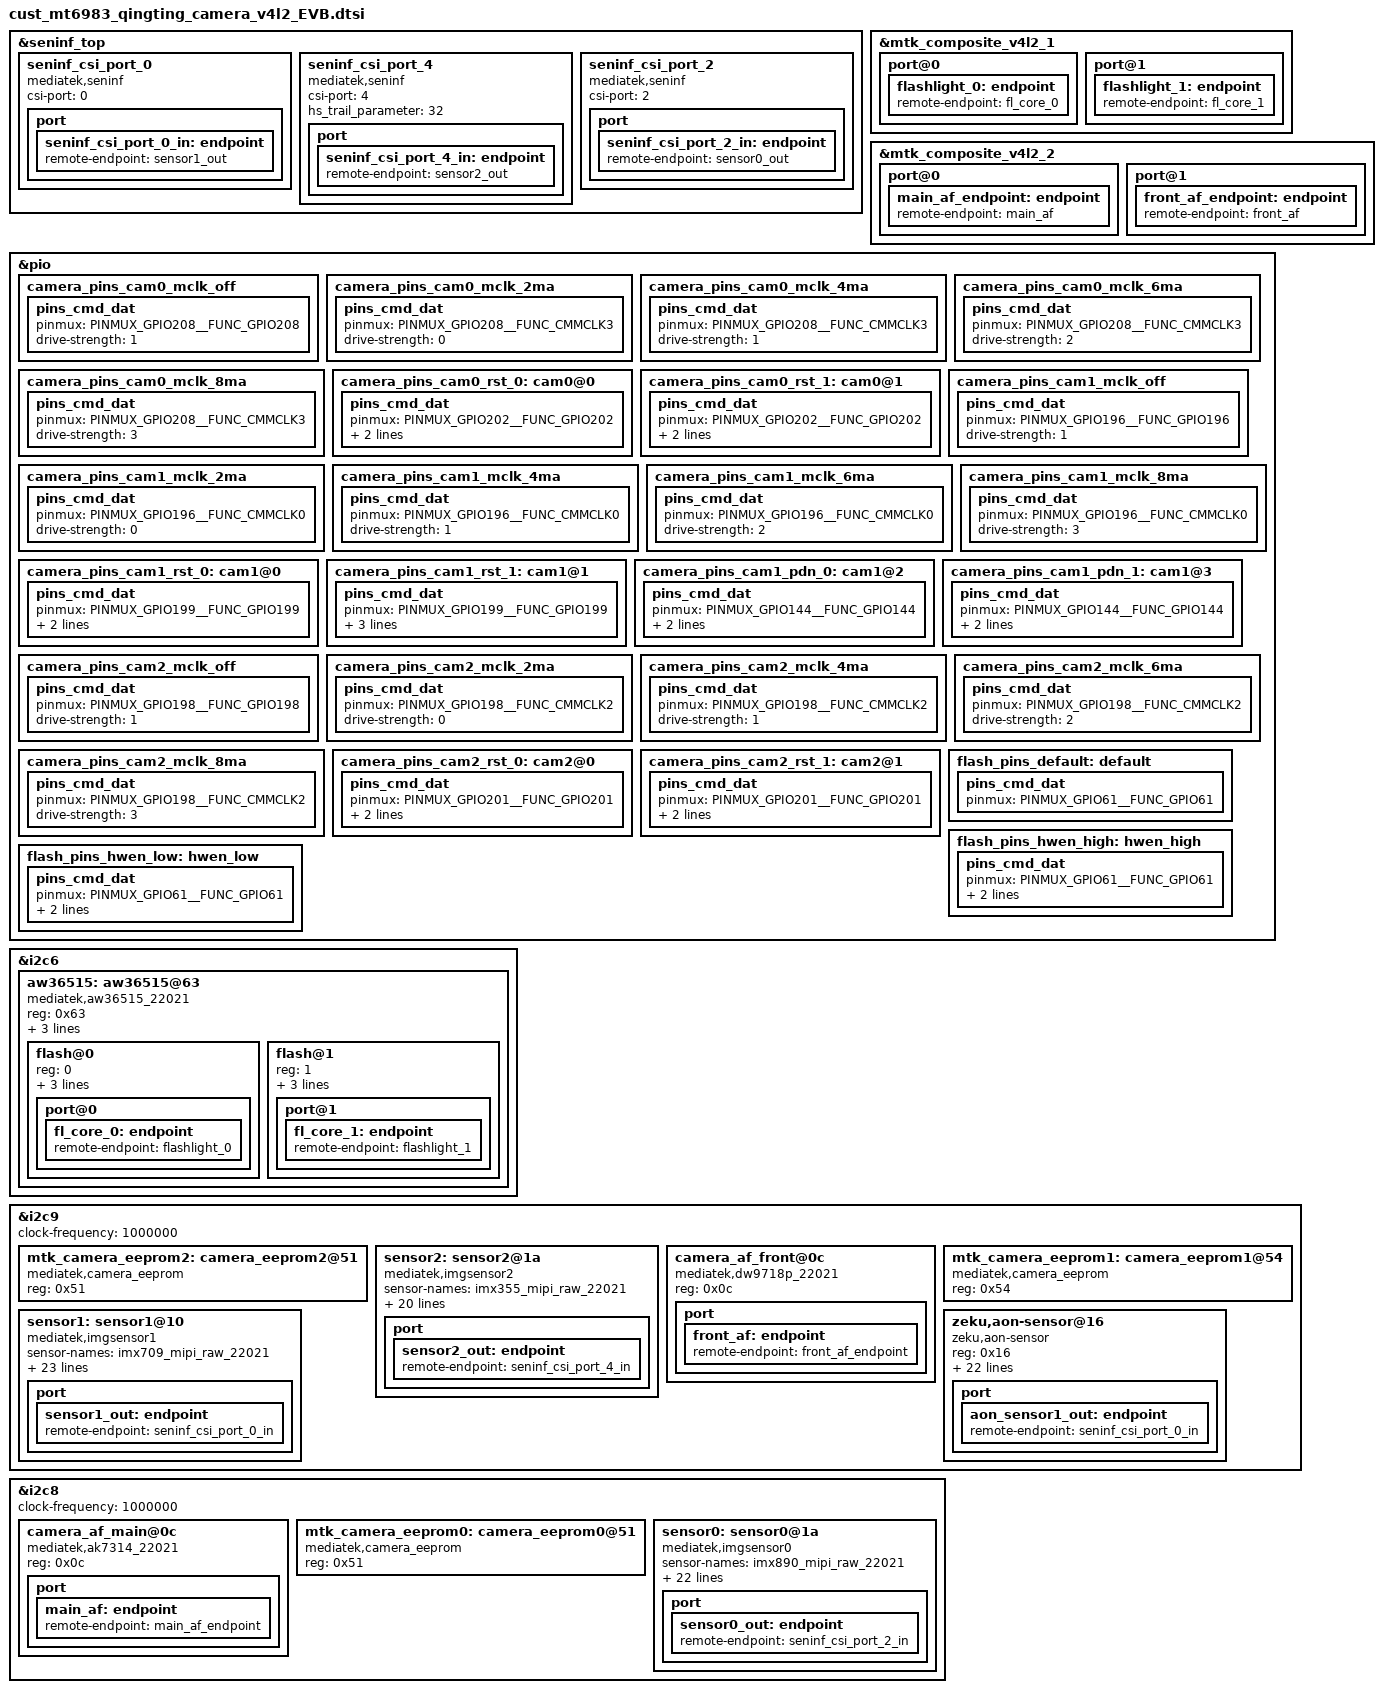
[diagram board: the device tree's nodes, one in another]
// SPDX-License-Identifier: GPL-2.0-only
/*
* Copyright (C) 2021 Oplus. All rights reserved.
*/

#include <dt-bindings/clock/mt6983-clk.h>

&seninf_top {
    seninf_csi_port_0: seninf_csi_port_0 {
        compatible = "mediatek,seninf";
        csi-port = "0";
        //seninf_dphy_settle_delay_dt = <14>;
#if 0
        nvmem-cells = <&csi_efuse0>;
        nvmem-cell-names = "rg_csi";
#endif
        port {
            seninf_csi_port_0_in: endpoint {
                remote-endpoint = <&sensor1_out>;
            };
        };
    };

    seninf_csi_port_4: seninf_csi_port_4 {
        compatible = "mediatek,seninf";
        csi-port = "4";
        hs_trail_parameter = <32>;
#if 0
        nvmem-cells = <&csi_efuse1>;
        nvmem-cell-names = "rg_csi";
#endif
        port {
            seninf_csi_port_4_in: endpoint {
                remote-endpoint = <&sensor2_out>;
            };
        };
    };

    seninf_csi_port_2: seninf_csi_port_2 {
        compatible = "mediatek,seninf";
        csi-port = "2";
#if 0
        nvmem-cells = <&csi_efuse2>;
        nvmem-cell-names = "rg_csi";
#endif
        port {
            seninf_csi_port_2_in: endpoint {
                remote-endpoint = <&sensor0_out>;
            };
        };
    };
};

&mtk_composite_v4l2_1 {
port@0 {
        flashlight_0: endpoint {
            remote-endpoint = <&fl_core_0>;
        };
    };
    port@1 {
        flashlight_1: endpoint {
            remote-endpoint = <&fl_core_1>;
        };
    };
};

&mtk_composite_v4l2_2 {
    port@0 {
        main_af_endpoint: endpoint {
            remote-endpoint = <&main_af>;
        };
    };
    port@1 {
        front_af_endpoint: endpoint {
            remote-endpoint = <&front_af>;
        };
    };
};

&pio {
    camera_pins_cam0_mclk_off: camera_pins_cam0_mclk_off {
        pins_cmd_dat {
            pinmux = <PINMUX_GPIO208__FUNC_GPIO208>;
            drive-strength = <1>;
        };
    };
    camera_pins_cam0_mclk_2ma: camera_pins_cam0_mclk_2ma {
        pins_cmd_dat {
            pinmux = <PINMUX_GPIO208__FUNC_CMMCLK3>;
            drive-strength = <0>;
        };
    };
    camera_pins_cam0_mclk_4ma: camera_pins_cam0_mclk_4ma {
        pins_cmd_dat {
            pinmux = <PINMUX_GPIO208__FUNC_CMMCLK3>;
            drive-strength = <1>;
        };
    };
    camera_pins_cam0_mclk_6ma: camera_pins_cam0_mclk_6ma {
        pins_cmd_dat {
            pinmux = <PINMUX_GPIO208__FUNC_CMMCLK3>;
            drive-strength = <2>;
        };
    };
    camera_pins_cam0_mclk_8ma: camera_pins_cam0_mclk_8ma {
        pins_cmd_dat {
            pinmux = <PINMUX_GPIO208__FUNC_CMMCLK3>;
            drive-strength = <3>;
        };
    };
    camera_pins_cam0_rst_0: cam0@0 {
        pins_cmd_dat {
            pinmux = <PINMUX_GPIO202__FUNC_GPIO202>;
            slew-rate = <1>;
            output-low;
        };
    };
    camera_pins_cam0_rst_1: cam0@1 {
        pins_cmd_dat {
            pinmux = <PINMUX_GPIO202__FUNC_GPIO202>;
            slew-rate = <1>;
            output-high;
        };
    };

    camera_pins_cam1_mclk_off: camera_pins_cam1_mclk_off {
        pins_cmd_dat {
            pinmux = <PINMUX_GPIO196__FUNC_GPIO196>;
            drive-strength = <1>;
        };
    };
    camera_pins_cam1_mclk_2ma: camera_pins_cam1_mclk_2ma {
        pins_cmd_dat {
            pinmux = <PINMUX_GPIO196__FUNC_CMMCLK0>;
            drive-strength = <0>;
        };
    };
    camera_pins_cam1_mclk_4ma: camera_pins_cam1_mclk_4ma {
        pins_cmd_dat {
            pinmux = <PINMUX_GPIO196__FUNC_CMMCLK0>;
            drive-strength = <1>;
        };
    };
    camera_pins_cam1_mclk_6ma: camera_pins_cam1_mclk_6ma {
        pins_cmd_dat {
            pinmux = <PINMUX_GPIO196__FUNC_CMMCLK0>;
            drive-strength = <2>;
        };
    };
    camera_pins_cam1_mclk_8ma: camera_pins_cam1_mclk_8ma {
        pins_cmd_dat {
            pinmux = <PINMUX_GPIO196__FUNC_CMMCLK0>;
            drive-strength = <3>;
        };
    };
    camera_pins_cam1_rst_0: cam1@0 {
        pins_cmd_dat {
            pinmux = <PINMUX_GPIO199__FUNC_GPIO199>;
            slew-rate = <1>;
            output-low;
        };
    };
    camera_pins_cam1_rst_1: cam1@1 {
        pins_cmd_dat {
            pinmux = <PINMUX_GPIO199__FUNC_GPIO199>;
            drive-strength = <3>;
            slew-rate = <1>;
            output-high;
        };
    };
    camera_pins_cam1_pdn_0: cam1@2 {
        pins_cmd_dat {
            pinmux = <PINMUX_GPIO144__FUNC_GPIO144>;
            slew-rate = <1>;
            output-low;
        };
    };
    camera_pins_cam1_pdn_1: cam1@3 {
        pins_cmd_dat {
            pinmux = <PINMUX_GPIO144__FUNC_GPIO144>;
            slew-rate = <1>;
            output-high;
        };
    };

    camera_pins_cam2_mclk_off: camera_pins_cam2_mclk_off {
        pins_cmd_dat {
            pinmux = <PINMUX_GPIO198__FUNC_GPIO198>;
            drive-strength = <1>;
        };
    };
    camera_pins_cam2_mclk_2ma: camera_pins_cam2_mclk_2ma {
        pins_cmd_dat {
            pinmux = <PINMUX_GPIO198__FUNC_CMMCLK2>;
            drive-strength = <0>;
        };
    };
    camera_pins_cam2_mclk_4ma: camera_pins_cam2_mclk_4ma {
        pins_cmd_dat {
            pinmux = <PINMUX_GPIO198__FUNC_CMMCLK2>;
            drive-strength = <1>;
        };
    };
    camera_pins_cam2_mclk_6ma: camera_pins_cam2_mclk_6ma {
        pins_cmd_dat {
            pinmux = <PINMUX_GPIO198__FUNC_CMMCLK2>;
            drive-strength = <2>;
        };
    };
    camera_pins_cam2_mclk_8ma: camera_pins_cam2_mclk_8ma {
        pins_cmd_dat {
            pinmux = <PINMUX_GPIO198__FUNC_CMMCLK2>;
            drive-strength = <3>;
        };
    };
    camera_pins_cam2_rst_0: cam2@0 {
        pins_cmd_dat {
            pinmux = <PINMUX_GPIO201__FUNC_GPIO201>;
            slew-rate = <1>;
            output-low;
        };
    };
    camera_pins_cam2_rst_1: cam2@1 {
        pins_cmd_dat {
            pinmux = <PINMUX_GPIO201__FUNC_GPIO201>;
            slew-rate = <1>;
            output-high;
        };
    };

    flash_pins_default: default {
            pins_cmd_dat {
                    pinmux = <PINMUX_GPIO61__FUNC_GPIO61>;
            };
    };

    flash_pins_hwen_high: hwen_high {
            pins_cmd_dat {
                    pinmux = <PINMUX_GPIO61__FUNC_GPIO61>;
                    slew-rate = <1>;
                    output-high;
            };
    };

    flash_pins_hwen_low: hwen_low {
            pins_cmd_dat {
                    pinmux = <PINMUX_GPIO61__FUNC_GPIO61>;
                    slew-rate = <1>;
                    output-low;
            };
    };
};

/*Flash light*/
&i2c6 {
    aw36515:aw36515@63 {
        compatible = "mediatek,aw36515_22021";
        reg = <0x63>;
        #cooling-cells = <2>;
        pinctrl-names = "default", "hwen_high", "hwen_low";
        pinctrl-0 = <&flash_pins_default>;
        pinctrl-1 = <&flash_pins_hwen_high>;
        pinctrl-2 = <&flash_pins_hwen_low>;
        status = "okay";
        flash@0{
            reg = <0>;
            type = <0>;
            ct = <0>;
            part = <0>;
            port@0 {
                fl_core_0: endpoint {
                    remote-endpoint = <&flashlight_0>;
                };
            };
        };
        flash@1{
            reg = <1>;
            type = <0>;
            ct = <1>;
            part = <0>;
            port@1 {
                fl_core_1: endpoint {
                    remote-endpoint = <&flashlight_1>;
                };
            };
        };
    };
};

&i2c9 {
    clock-frequency = <1000000>;
    mtk_camera_eeprom2:camera_eeprom2@51 {
        compatible = "mediatek,camera_eeprom";
        reg = <0x51>;
        status = "okay";
    };

    sensor2: sensor2@1a {
        compatible = "mediatek,imgsensor2";
        sensor-names = "imx355_mipi_raw_22021";
        reg = <0x1a>;
        pinctrl-names = "mclk_off",
                "mclk_2mA",
                "mclk_4mA",
                "mclk_6mA",
                "mclk_8mA",
                "rst_low",
                "rst_high";
        //GPIO198
        pinctrl-0 = <&camera_pins_cam2_mclk_off>;
        pinctrl-1 = <&camera_pins_cam2_mclk_2ma>;
        pinctrl-2 = <&camera_pins_cam2_mclk_4ma>;
        pinctrl-3 = <&camera_pins_cam2_mclk_6ma>;
        pinctrl-4 = <&camera_pins_cam2_mclk_8ma>;
        //GPIO201
        pinctrl-5 = <&camera_pins_cam2_rst_0>;
        pinctrl-6 = <&camera_pins_cam2_rst_1>;

        dvdd-supply = <&wl2868c_ldo1a>;
        avdd-supply = <&wl2868c_ldo5a>;
        dovdd-supply = <&fan53870_ldo6b>;

        clocks = <&topckgen_clk CLK_TOPCKGEN_UNIVPLL_192M_D32>,
            <&topckgen_clk CLK_TOPCKGEN_UNIVPLL_192M_D16>,
            <&topckgen_clk CLK_TOPCKGEN_F_F26M_CK_D2>,
            <&topckgen_clk CLK_TOPCKGEN_UNIVPLL_192M_D10>,
            <&topckgen_clk CLK_TOPCKGEN_UNIVPLL_192M_D8>,
            <&clk26m>,
            <&topckgen_clk CLK_TOPCKGEN_UNIVPLL_D6_D8>,
            <&topckgen_clk CLK_TOPCKGEN_CAMTG3_SEL>;
        clock-names = "6", "12", "13", "19.2", "24", "26", "52", "mclk";

        status = "okay";

        port {
            sensor2_out: endpoint {
                remote-endpoint = <&seninf_csi_port_4_in>;
            };
        };
    };
};

&i2c8 {
    clock-frequency = <1000000>;
    /* MAIN */
    camera_af_main@0c {
        compatible = "mediatek,ak7314_22021";
        reg = <0x0c>;
        port {
            main_af: endpoint {
                remote-endpoint = <&main_af_endpoint>;
            };
        };
    };
    mtk_camera_eeprom0:camera_eeprom0@51 {
        compatible = "mediatek,camera_eeprom";
        reg = <0x51>;
        status = "okay";
    };

    sensor0: sensor0@1a {
        compatible = "mediatek,imgsensor0";
        sensor-names = "imx890_mipi_raw_22021";
        reg = <0x1a>;
        pinctrl-names = "mclk_off",
                "mclk_2mA",
                "mclk_4mA",
                "mclk_6mA",
                "mclk_8mA",
                "rst_low",
                "rst_high";
        //GPIO208
        pinctrl-0 = <&camera_pins_cam0_mclk_off>;
        pinctrl-1 = <&camera_pins_cam0_mclk_2ma>;
        pinctrl-2 = <&camera_pins_cam0_mclk_4ma>;
        pinctrl-3 = <&camera_pins_cam0_mclk_6ma>;
        pinctrl-4 = <&camera_pins_cam0_mclk_8ma>;
        //GPIO202
        pinctrl-5 = <&camera_pins_cam0_rst_0>;
        pinctrl-6 = <&camera_pins_cam0_rst_1>;

        avdd-supply = <&wl2868c_ldo3a>;
        avdd1-supply = <&fan53870_ldo5b>;
        afvdd-supply = <&wl2868c_ldo6a>;
        dvdd-supply = <&wl2868c_ldo2a>;
        dovdd-supply = <&fan53870_ldo6b>;

        clocks = <&topckgen_clk CLK_TOPCKGEN_UNIVPLL_192M_D32>,
            <&topckgen_clk CLK_TOPCKGEN_UNIVPLL_192M_D16>,
            <&topckgen_clk CLK_TOPCKGEN_F_F26M_CK_D2>,
            <&topckgen_clk CLK_TOPCKGEN_UNIVPLL_192M_D10>,
            <&topckgen_clk CLK_TOPCKGEN_UNIVPLL_192M_D8>,
            <&clk26m>,
            <&topckgen_clk CLK_TOPCKGEN_UNIVPLL_D6_D8>,
            <&topckgen_clk CLK_TOPCKGEN_CAMTG4_SEL>;
        clock-names = "6", "12", "13", "19.2", "24", "26", "52", "mclk";

        status = "okay";

        port {
            sensor0_out: endpoint {
                remote-endpoint = <&seninf_csi_port_2_in>;
            };
        };
    };
};

&i2c9 {
    clock-frequency = <1000000>;
    /* FRONT */
    camera_af_front@0c {
        compatible = "mediatek,dw9718p_22021";
        reg = <0x0c>;
        port {
            front_af: endpoint {
                remote-endpoint = <&front_af_endpoint>;
            };
        };
    };
    mtk_camera_eeprom1:camera_eeprom1@54 {
        compatible = "mediatek,camera_eeprom";
        reg = <0x54>;
        status = "okay";
    };
    sensor1: sensor1@10 {
        compatible = "mediatek,imgsensor1";
        sensor-names = "imx709_mipi_raw_22021";
        reg = <0x10>;
        pinctrl-names = "mclk_off",
                "mclk_2mA",
                "mclk_4mA",
                "mclk_6mA",
                "mclk_8mA",
                "rst_low",
                "rst_high",
                "pdn_low",
                "pdn_high";
        pinctrl-0 = <&camera_pins_cam1_mclk_off>;
        pinctrl-1 = <&camera_pins_cam1_mclk_2ma>;
        pinctrl-2 = <&camera_pins_cam1_mclk_4ma>;
        pinctrl-3 = <&camera_pins_cam1_mclk_6ma>;
        pinctrl-4 = <&camera_pins_cam1_mclk_8ma>;
        pinctrl-5 = <&camera_pins_cam1_rst_0>;
        pinctrl-6 = <&camera_pins_cam1_rst_1>;
        pinctrl-7 = <&camera_pins_cam1_pdn_0>;
        pinctrl-8 = <&camera_pins_cam1_pdn_1>;

        avdd-supply = <&wl2868c_ldo4a>;
        afvdd-supply = <&wl2868c_ldo7a>;
        dvdd-supply = <&fan53870_ldo1b>;
        dovdd-supply = <&fan53870_ldo6b>;

        clocks = <&topckgen_clk CLK_TOPCKGEN_UNIVPLL_192M_D32>,
            <&topckgen_clk CLK_TOPCKGEN_UNIVPLL_192M_D16>,
            <&topckgen_clk CLK_TOPCKGEN_F_F26M_CK_D2>,
            <&topckgen_clk CLK_TOPCKGEN_UNIVPLL_192M_D10>,
            <&topckgen_clk CLK_TOPCKGEN_UNIVPLL_192M_D8>,
            <&clk26m>,
            <&topckgen_clk CLK_TOPCKGEN_UNIVPLL_D6_D8>,
            <&topckgen_clk CLK_TOPCKGEN_CAMTG_SEL>;
        clock-names = "6", "12", "13", "19.2", "24", "26", "52", "mclk";

        status = "okay";

        port {
            sensor1_out: endpoint {
                remote-endpoint = <&seninf_csi_port_0_in>;
            };
        };
    };
    zeku,aon-sensor@16 {
        compatible = "zeku,aon-sensor";
        reg = <0x16>;
        cell-index = <1>;
        #thermal-sensor-cells = <0>;
        pinctrl-names = "mclk_off",
                "mclk_2mA",
                "mclk_4mA",
                "mclk_6mA",
                "mclk_8mA",
                "rst_low",
                "rst_high",
                "pdn_low",
                "pdn_high";
        pinctrl-0 = <&camera_pins_cam1_mclk_off>;
        pinctrl-1 = <&camera_pins_cam1_mclk_2ma>;
        pinctrl-2 = <&camera_pins_cam1_mclk_4ma>;
        pinctrl-3 = <&camera_pins_cam1_mclk_6ma>;
        pinctrl-4 = <&camera_pins_cam1_mclk_8ma>;
        pinctrl-5 = <&camera_pins_cam1_rst_0>;
        pinctrl-6 = <&camera_pins_cam1_rst_1>;
        pinctrl-7 = <&camera_pins_cam1_pdn_0>;
        pinctrl-8 = <&camera_pins_cam1_pdn_1>;

        avdd-supply = <&wl2868c_ldo4a>;
        dvdd-supply = <&fan53870_ldo1b>;
        dovdd-supply = <&fan53870_ldo6b>;
        afvdd-supply = <&wl2868c_ldo7a>;
        regulator-names = "avdd", "dvdd","dovdd", "afvdd";
        clocks = <&topckgen_clk CLK_TOP_UNIVPLL_192M_D32>,
            <&topckgen_clk CLK_TOP_UNIVPLL_192M_D16>,
            <&topckgen_clk CLK_TOP_F26M_CK_D2>,
            <&topckgen_clk CLK_TOP_UNIVPLL_192M_D10>,
            <&topckgen_clk CLK_TOP_UNIVPLL_192M_D8>,
            <&clk26m>,
            <&topckgen_clk CLK_TOP_UNIVPLL_D6_D8>,
            <&topckgen_clk CLK_TOP_CAMTG4_SEL>;
        clock-names = "6", "12", "13", "19.2", "24", "26", "52", "mclk";

        status = "okay";

        port {
            aon_sensor1_out: endpoint {
                remote-endpoint = <&seninf_csi_port_0_in>;
            };
        };
    };
};

